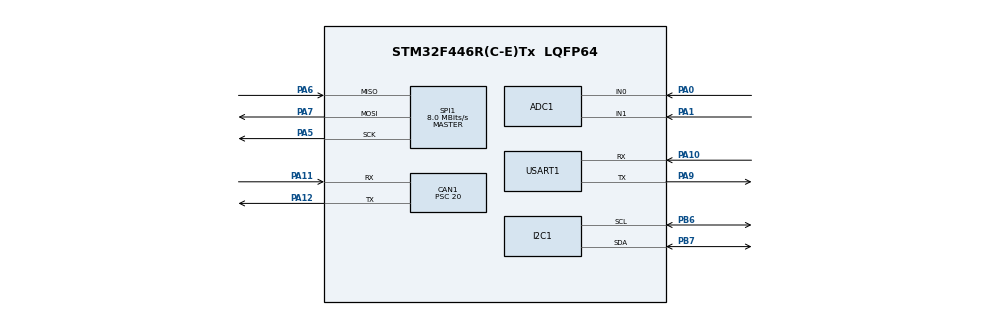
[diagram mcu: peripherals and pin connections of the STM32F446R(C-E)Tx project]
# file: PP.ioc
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ADC1.Channel-0\#ChannelRegularConversion=ADC_CHANNEL_0
ADC1.NbrOfConversionFlag=1
ADC1.Rank-0\#ChannelRegularConversion=1
ADC1.SamplingTime-0\#ChannelRegularConversion=ADC_SAMPLETIME_3CYCLES
ADC1.master=1
CAN1.BS1=CAN_BS1_3TQ
CAN1.BS2=CAN_BS2_4TQ
CAN1.CalculateBaudRate=100000
CAN1.CalculateTimeBit=10000
CAN1.CalculateTimeQuantum=1250.0
CAN1.Prescaler=20
Dma.Request0=SPI1_TX
Dma.SPI1_TX.0.Direction=DMA_MEMORY_TO_PERIPH
Dma.SPI1_TX.0.FIFOMode=DMA_FIFOMODE_DISABLE
Dma.SPI1_TX.0.Instance=DMA2_Stream3
Dma.SPI1_TX.0.MemDataAlignment=DMA_MDATAALIGN_BYTE
Dma.SPI1_TX.0.MemInc=DMA_MINC_ENABLE
Dma.SPI1_TX.0.Mode=DMA_NORMAL
Dma.SPI1_TX.0.PeriphDataAlignment=DMA_PDATAALIGN_BYTE
Dma.SPI1_TX.0.PeriphInc=DMA_PINC_DISABLE
Dma.SPI1_TX.0.Priority=DMA_PRIORITY_LOW
Mcu.Family=STM32F4
Mcu.Name=STM32F446R(C-E)Tx
Mcu.Package=LQFP64
NVIC.DMA2_Stream3_IRQn=true\:0\:0\:false\:false\:true\:false\:true\:true
NVIC.PriorityGroup=NVIC_PRIORITYGROUP_4
NVIC.SPI1_IRQn=true\:0\:0\:false\:false\:true\:true\:true\:true
PA0-WKUP.Signal=ADCx_IN0
PA1.Signal=ADCx_IN1
PA10.Mode=Asynchronous
PA10.Signal=USART1_RX
PA11.Mode=CAN_Activate
PA11.Signal=CAN1_RX
PA12.Mode=CAN_Activate
PA12.Signal=CAN1_TX
PA5.Mode=Full_Duplex_Master
PA5.Signal=SPI1_SCK
PA6.Mode=Full_Duplex_Master
PA6.Signal=SPI1_MISO
PA7.Mode=Full_Duplex_Master
PA7.Signal=SPI1_MOSI
PA9.Mode=Asynchronous
PA9.Signal=USART1_TX
PB6.Mode=I2C
PB6.Signal=I2C1_SCL
PB7.Mode=I2C
PB7.Signal=I2C1_SDA
ProjectManager.HeapSize=0x200
ProjectManager.StackSize=0x400
ProjectManager.TargetToolchain=STM32CubeIDE
RCC.CortexFreq_Value=16000000
RCC.USBFreq_Value=96000000
RCC.VCOOutputFreq_Value=192000000
SH.ADCx_IN0.0=ADC1_IN0,IN0
SH.ADCx_IN1.0=ADC1_IN1,IN1
SPI1.CalculateBaudRate=8.0 MBits/s
SPI1.Direction=SPI_DIRECTION_2LINES
SPI1.Mode=SPI_MODE_MASTER
SPI1.VirtualType=VM_MASTER
USART1.VirtualMode=VM_ASYNC
board=custom

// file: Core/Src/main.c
/* USER CODE BEGIN Header */
/**
  ******************************************************************************
  * @file           : main.c
  * @brief          : Main program body
  ******************************************************************************
  * @attention
  *
  * Copyright (c) 2024 STMicroelectronics.
  * All rights reserved.
  *
  * This software is licensed under terms that can be found in the LICENSE file
  * in the root directory of this software component.
  * If no LICENSE file comes with this software, it is provided AS-IS.
  *
  ******************************************************************************
  */
/* USER CODE END Header */
#include "main.h"

ADC_HandleTypeDef hadc1;

CAN_HandleTypeDef hcan1;

I2C_HandleTypeDef hi2c1;

SPI_HandleTypeDef hspi1;
DMA_HandleTypeDef hdma_spi1_tx;

UART_HandleTypeDef huart1;

/* USER CODE BEGIN PV */
/* Private variable */
unint8_t TX_Buffer []= "A"; //DATA to sent
/* USER CODE END PV */

void SystemClock_Config(void);
static void MX_GPIO_Init(void);
static void MX_DMA_Init(void);
static void MX_ADC1_Init(void);
static void MX_CAN1_Init(void);
static void MX_I2C1_Init(void);
static void MX_SPI1_Init(void);
static void MX_USART1_UART_Init(void);

int main(void)
{

  /* MCU Configuration--------------------------------------------------------*/

  /* Reset of all peripherals, Initializes the Flash interface and the Systick. */
  HAL_Init();

  /* Configure the system clock */
  SystemClock_Config();

  /* Initialize all configured peripherals */
  MX_GPIO_Init();
  MX_DMA_Init();
  MX_ADC1_Init();
  MX_CAN1_Init();
  MX_I2C1_Init();
  MX_SPI1_Init();
  MX_USART1_UART_Init();
  /* USER CODE BEGIN 2 */
  HAL_SPI_Transmit(&hspi1, TX_Buffer, 1, 1000); //Sending in Blocking mode
  HAL_Delay(100);
  /* USER CODE END 2 */

  /* Infinite loop */
  while (1)
  {

  }
}

void SystemClock_Config(void)
{
  RCC_OscInitTypeDef RCC_OscInitStruct = {0};
  RCC_ClkInitTypeDef RCC_ClkInitStruct = {0};

  /** Configure the main internal regulator output voltage
  */
  __HAL_RCC_PWR_CLK_ENABLE();
  __HAL_PWR_VOLTAGESCALING_CONFIG(PWR_REGULATOR_VOLTAGE_SCALE3);

  /** Initializes the RCC Oscillators according to the specified parameters
  * in the RCC_OscInitTypeDef structure.
  */
  RCC_OscInitStruct.OscillatorType = RCC_OSCILLATORTYPE_HSI;
  RCC_OscInitStruct.HSIState = RCC_HSI_ON;
  RCC_OscInitStruct.HSICalibrationValue = RCC_HSICALIBRATION_DEFAULT;
  RCC_OscInitStruct.PLL.PLLState = RCC_PLL_NONE;
  if (HAL_RCC_OscConfig(&RCC_OscInitStruct) != HAL_OK)
  {
    Error_Handler();
  }

  /** Initializes the CPU, AHB and APB buses clocks
  */
  RCC_ClkInitStruct.ClockType = RCC_CLOCKTYPE_HCLK|RCC_CLOCKTYPE_SYSCLK
                              |RCC_CLOCKTYPE_PCLK1|RCC_CLOCKTYPE_PCLK2;
  RCC_ClkInitStruct.SYSCLKSource = RCC_SYSCLKSOURCE_HSI;
  RCC_ClkInitStruct.AHBCLKDivider = RCC_SYSCLK_DIV1;
  RCC_ClkInitStruct.APB1CLKDivider = RCC_HCLK_DIV1;
  RCC_ClkInitStruct.APB2CLKDivider = RCC_HCLK_DIV1;

  if (HAL_RCC_ClockConfig(&RCC_ClkInitStruct, FLASH_LATENCY_0) != HAL_OK)
  {
    Error_Handler();
  }
}

static void MX_ADC1_Init(void)
{

  ADC_ChannelConfTypeDef sConfig = {0};

  /** Configure the global features of the ADC (Clock, Resolution, Data Alignment and number of conversion)
  */
  hadc1.Instance = ADC1;
  hadc1.Init.ClockPrescaler = ADC_CLOCK_SYNC_PCLK_DIV2;
  hadc1.Init.Resolution = ADC_RESOLUTION_12B;
  hadc1.Init.ScanConvMode = DISABLE;
  hadc1.Init.ContinuousConvMode = DISABLE;
  hadc1.Init.DiscontinuousConvMode = DISABLE;
  hadc1.Init.ExternalTrigConvEdge = ADC_EXTERNALTRIGCONVEDGE_NONE;
  hadc1.Init.ExternalTrigConv = ADC_SOFTWARE_START;
  hadc1.Init.DataAlign = ADC_DATAALIGN_RIGHT;
  hadc1.Init.NbrOfConversion = 1;
  hadc1.Init.DMAContinuousRequests = DISABLE;
  hadc1.Init.EOCSelection = ADC_EOC_SINGLE_CONV;
  if (HAL_ADC_Init(&hadc1) != HAL_OK)
  {
    Error_Handler();
  }

  /** Configure for the selected ADC regular channel its corresponding rank in the sequencer and its sample time.
  */
  sConfig.Channel = ADC_CHANNEL_0;
  sConfig.Rank = 1;
  sConfig.SamplingTime = ADC_SAMPLETIME_3CYCLES;
  if (HAL_ADC_ConfigChannel(&hadc1, &sConfig) != HAL_OK)
  {
    Error_Handler();
  }

}

static void MX_CAN1_Init(void)
{

  hcan1.Instance = CAN1;
  hcan1.Init.Prescaler = 20;
  hcan1.Init.Mode = CAN_MODE_NORMAL;
  hcan1.Init.SyncJumpWidth = CAN_SJW_1TQ;
  hcan1.Init.TimeSeg1 = CAN_BS1_3TQ;
  hcan1.Init.TimeSeg2 = CAN_BS2_4TQ;
  hcan1.Init.TimeTriggeredMode = DISABLE;
  hcan1.Init.AutoBusOff = DISABLE;
  hcan1.Init.AutoWakeUp = DISABLE;
  hcan1.Init.AutoRetransmission = DISABLE;
  hcan1.Init.ReceiveFifoLocked = DISABLE;
  hcan1.Init.TransmitFifoPriority = DISABLE;
  if (HAL_CAN_Init(&hcan1) != HAL_OK)
  {
    Error_Handler();
  }

}

static void MX_I2C1_Init(void)
{

  hi2c1.Instance = I2C1;
  hi2c1.Init.ClockSpeed = 100000;
  hi2c1.Init.DutyCycle = I2C_DUTYCYCLE_2;
  hi2c1.Init.OwnAddress1 = 0;
  hi2c1.Init.AddressingMode = I2C_ADDRESSINGMODE_7BIT;
  hi2c1.Init.DualAddressMode = I2C_DUALADDRESS_DISABLE;
  hi2c1.Init.OwnAddress2 = 0;
  hi2c1.Init.GeneralCallMode = I2C_GENERALCALL_DISABLE;
  hi2c1.Init.NoStretchMode = I2C_NOSTRETCH_DISABLE;
  if (HAL_I2C_Init(&hi2c1) != HAL_OK)
  {
    Error_Handler();
  }

}

static void MX_SPI1_Init(void)
{

  /* SPI1 parameter configuration*/
  hspi1.Instance = SPI1;
  hspi1.Init.Mode = SPI_MODE_MASTER;
  hspi1.Init.Direction = SPI_DIRECTION_2LINES;
  hspi1.Init.DataSize = SPI_DATASIZE_8BIT;
  hspi1.Init.CLKPolarity = SPI_POLARITY_LOW;
  hspi1.Init.CLKPhase = SPI_PHASE_1EDGE;
  hspi1.Init.NSS = SPI_NSS_SOFT;
  hspi1.Init.BaudRatePrescaler = SPI_BAUDRATEPRESCALER_2;
  hspi1.Init.FirstBit = SPI_FIRSTBIT_MSB;
  hspi1.Init.TIMode = SPI_TIMODE_DISABLE;
  hspi1.Init.CRCCalculation = SPI_CRCCALCULATION_DISABLE;
  hspi1.Init.CRCPolynomial = 10;
  if (HAL_SPI_Init(&hspi1) != HAL_OK)
  {
    Error_Handler();
  }

}

static void MX_USART1_UART_Init(void)
{

  huart1.Instance = USART1;
  huart1.Init.BaudRate = 115200;
  huart1.Init.WordLength = UART_WORDLENGTH_8B;
  huart1.Init.StopBits = UART_STOPBITS_1;
  huart1.Init.Parity = UART_PARITY_NONE;
  huart1.Init.Mode = UART_MODE_TX_RX;
  huart1.Init.HwFlowCtl = UART_HWCONTROL_NONE;
  huart1.Init.OverSampling = UART_OVERSAMPLING_16;
  if (HAL_UART_Init(&huart1) != HAL_OK)
  {
    Error_Handler();
  }

}

static void MX_DMA_Init(void)
{

  /* DMA controller clock enable */
  __HAL_RCC_DMA2_CLK_ENABLE();

  /* DMA interrupt init */
  /* DMA2_Stream3_IRQn interrupt configuration */
  HAL_NVIC_SetPriority(DMA2_Stream3_IRQn, 0, 0);
  HAL_NVIC_EnableIRQ(DMA2_Stream3_IRQn);

}

static void MX_GPIO_Init(void)
{

  /* GPIO Ports Clock Enable */
  __HAL_RCC_GPIOA_CLK_ENABLE();
  __HAL_RCC_GPIOB_CLK_ENABLE();

}

void Error_Handler(void)
{
  __disable_irq();
  while (1)
  {
  }
}
